AUTOSAR XML (schema 00046)
package /ComponentTypes
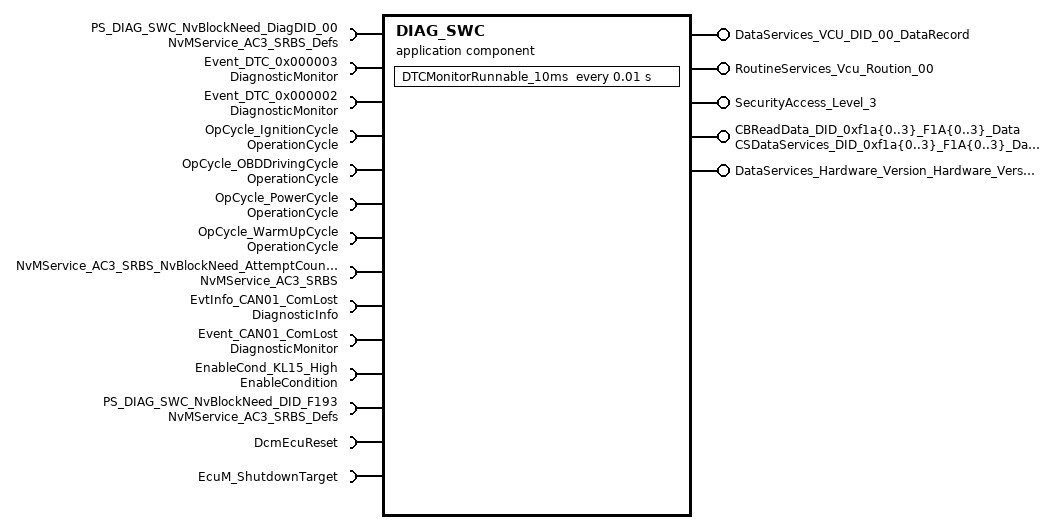
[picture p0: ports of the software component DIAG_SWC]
  application sw component type DIAG_SWC
    provide port DataServices_VCU_DID_00_DataRecord: provided-interface=DataServices_VCU_DID_00_DataRecord
      provided-com-specs:
        operation=ReadData, queue-length=1
        operation=ConditionCheckRead, queue-length=1
        operation=WriteData, queue-length=1
    require port PS_DIAG_SWC_NvBlockNeed_DiagDID_00: required-com-specs=[GetErrorStatus, SetRamBlockStatus, ReadBlock, WriteBlock, RestoreBlockDefaults, InvalidateNvBlock, EraseBlock], required-interface=NvMService_AC3_SRBS_Defs
    provide port RoutineServices_Vcu_Roution_00: provided-interface=RoutineServices_Vcu_Roution_00
      provided-com-specs:
        operation=Start, queue-length=1
        operation=Stop, queue-length=1
        operation=RequestResults, queue-length=1
    6 x require port:
      Event_DTC_0x000003: required-interface=DiagnosticMonitor
        required-com-specs:
          SetEventStatus
          ResetEventStatus
          ResetEventDebounceStatus
          GetEventUdsStatus
          GetEventStatus
          GetEventFailed
          GetEventTested
          GetDTCOfEvent
          GetFaultDetectionCounter
          GetEventFreezeFrameDataEx
          GetEventExtendedDataRecordEx
      Event_DTC_0x000002: required-interface=DiagnosticMonitor
        required-com-specs:
          SetEventStatus
          ResetEventStatus
          ResetEventDebounceStatus
          GetEventUdsStatus
          GetEventStatus
          GetEventFailed
          GetEventTested
          GetDTCOfEvent
          GetFaultDetectionCounter
          GetEventFreezeFrameDataEx
          GetEventExtendedDataRecordEx
      OpCycle_IgnitionCycle: required-com-specs=[GetOperationCycleState, SetOperationCycleState], required-interface=OperationCycle
      OpCycle_OBDDrivingCycle: required-com-specs=[GetOperationCycleState, SetOperationCycleState], required-interface=OperationCycle
      OpCycle_PowerCycle: required-com-specs=[GetOperationCycleState, SetOperationCycleState], required-interface=OperationCycle
      OpCycle_WarmUpCycle: required-com-specs=[GetOperationCycleState, SetOperationCycleState], required-interface=OperationCycle
    provide port SecurityAccess_Level_3: provided-interface=SecurityAccess_Level_3
      provided-com-specs:
        operation=GetSeed, queue-length=1
        operation=CompareKey, queue-length=1
        operation=GetSecurityAttemptCounter, queue-length=1
        operation=SetSecurityAttemptCounter, queue-length=1
    require port NvMService_AC3_SRBS_NvBlockNeed_AttemptCounter: required-com-specs=[WriteBlock, SetRamBlockStatus, ReadBlock, InvalidateNvBlock, GetErrorStatus, EraseBlock], required-interface=NvMService_AC3_SRBS
    4 x provide port, all with server-com-spec{operation=ReadData, queue-length=1}:
      CBReadData_DID_0xf1a{0..3}_F1A{0..3}_Data: provided-interface=CSDataServices_DID_0xf1a{0..3}_F1A{0..3}_Data
    4 x require port:
      EvtInfo_CAN01_ComLost: required-interface=DiagnosticInfo
        required-com-specs:
          GetEventUdsStatus
          GetEventStatus
          GetEventFailed
          GetEventTested
          GetDTCOfEvent
          GetFaultDetectionCounter
          GetEventFreezeFrameDataEx
          GetEventExtendedDataRecordEx
          GetEventEnableCondition
          GetDebouncingOfEvent
          GetMonitorStatus
      Event_CAN01_ComLost: required-interface=DiagnosticMonitor
        required-com-specs:
          SetEventStatus
          ResetEventStatus
          ResetEventDebounceStatus
          GetEventUdsStatus
          GetEventStatus
          GetEventFailed
          GetEventTested
          GetDTCOfEvent
          GetFaultDetectionCounter
          GetEventFreezeFrameDataEx
          GetEventExtendedDataRecordEx
      EnableCond_KL15_High: client-com-spec=SetEnableCondition, required-interface=EnableCondition
      PS_DIAG_SWC_NvBlockNeed_DID_F193: required-com-specs=[GetErrorStatus, SetRamBlockStatus, ReadBlock, WriteBlock, RestoreBlockDefaults, InvalidateNvBlock, EraseBlock], required-interface=NvMService_AC3_SRBS_Defs
    provide port DataServices_Hardware_Version_Hardware_Version_Number: provided-interface=DataServices_Hardware_Version_Hardware_Version_Number
      provided-com-specs:
        operation=ReadData, queue-length=1
        operation=ConditionCheckRead, queue-length=1
        operation=WriteData, queue-length=1
    require port DcmEcuReset: mode-switch-receiver-com-spec=DcmEcuReset, required-interface=DcmEcuReset
    require port EcuM_ShutdownTarget: required-com-specs=[SelectShutdownTarget, GetShutdownTarget, GetLastShutdownTarget, SelectShutdownCause, GetShutdownCause], required-interface=EcuM_ShutdownTarget
    behavior DIAG_SWC_InternalBehavior
      ar-typed-per-instance-memorys:
        data NvBlockNeed_DiagDID_00_MirrorBlock: sw-calibration-access=READ-WRITE, type=NvM_Arry4Bytes
        data NvBlockNeed_AttemptCounter_MirrorBlock: sw-calibration-access=READ-WRITE, type=uint8
        data NvBlockNeed_DID_F193_MirrorBlock: sw-calibration-access=READ-ONLY, type=NvM_Arry4Bytes
      6 x operation invoked event:
        OIT_DataServices_VCU_DID_00_DataRecord_WriteData_DataServices_VCU_DID_00_DataRecord_WriteData: start-on-event=DataServices_VCU_DID_00_DataRecord_WriteData, operation=DataServices_VCU_DID_00_DataRecord.WriteData
        OIT_DataServices_VCU_DID_00_DataRecord_ConditionCheckRead_DataServices_VCU_DID_00_DataRecord_ConditionCheckRead: start-on-event=DataServices_VCU_DID_00_DataRecord_ConditionCheckRead, operation=DataServices_VCU_DID_00_DataRecord.ConditionCheckRead
        OIT_DataServices_VCU_DID_00_DataRecord_ReadData_DataServices_VCU_DID_00_DataRecord_ReadData: start-on-event=DataServices_VCU_DID_00_DataRecord_ReadData, operation=DataServices_VCU_DID_00_DataRecord.ReadData
        OIT_RoutineServices_Vcu_Roution_00_RequestResults_RoutineServices_Vcu_Roution_00_RequestResults: start-on-event=RoutineServices_Vcu_Roution_00_RequestResults, operation=RoutineServices_Vcu_Roution_00.RequestResults
        OIT_RoutineServices_Vcu_Roution_00_Stop_RoutineServices_Vcu_Roution_00_Stop: start-on-event=RoutineServices_Vcu_Roution_00_Stop, operation=RoutineServices_Vcu_Roution_00.Stop
        OIT_RoutineServices_Vcu_Roution_00_Start_RoutineServices_Vcu_Roution_00_Start: start-on-event=RoutineServices_Vcu_Roution_00_Start, operation=RoutineServices_Vcu_Roution_00.Start
      init event DIAG_SWC_InitEvent: start-on-event=DIAG_SWC_Init
      timing event TMT_DTCMonitorRunnable_10ms: start-on-event=DTCMonitorRunnable_10ms, period=0.01
      11 x operation invoked event:
        OIT_SecurityAccess_Level_3_SetSecurityAttemptCounter_SecurityAccess_Level_3_SetSecurityAttemptCounter: start-on-event=SecurityAccess_Level_3_SetSecurityAttemptCounter, operation=SecurityAccess_Level_3.SetSecurityAttemptCounter
        OIT_SecurityAccess_Level_3_GetSecurityAttemptCounter_SecurityAccess_Level_3_GetSecurityAttemptCounter: start-on-event=SecurityAccess_Level_3_GetSecurityAttemptCounter, operation=SecurityAccess_Level_3.GetSecurityAttemptCounter
        OIT_SecurityAccess_Level_3_CompareKey_SecurityAccess_Level_3_CompareKey: start-on-event=SecurityAccess_Level_3_CompareKey, operation=SecurityAccess_Level_3.CompareKey
        OIT_SecurityAccess_Level_3_GetSeed_SecurityAccess_Level_3_GetSeed: start-on-event=SecurityAccess_Level_3_GetSeed, operation=SecurityAccess_Level_3.GetSeed
        OIT_CBReadData_DID_0xf1a{0..3}_F1A{0..3}_Data_ReadData_CBReadData_DID_0xf1a{0..3}_F1A{0..3}_Data_ReadData: start-on-event=CBReadData_DID_0xf1a{0..3}_F1A{0..3}_Data_ReadData, operation=CBReadData_DID_0xf1a{0..3}_F1A{0..3}_Data.ReadData
        OIT_DataServices_Hardware_Version_Hardware_Version_Number_WriteData_DataServices_Hardware_Version_Hardware_Version_Numbe125FF288: start-on-event=DataServices_Hardware_Version_Hardware_Version_Number_WriteData, operation=DataServices_Hardware_Version_Hardware_Version_Number.WriteData
        OIT_DataServices_Hardware_Version_Hardware_Version_Number_ConditionCheckRead_DataServices_Hardware_Version_Hardware_Vers10245F7A: start-on-event=DataServices_Hardware_Version_Hardware_Version_Number_ConditionCheckRead, operation=DataServices_Hardware_Version_Hardware_Version_Number.ConditionCheckRead
        OIT_DataServices_Hardware_Version_Hardware_Version_Number_ReadData_DataServices_Hardware_Version_Hardware_Version_Number62630144: start-on-event=DataServices_Hardware_Version_Hardware_Version_Number_ReadData, operation=DataServices_Hardware_Version_Hardware_Version_Number.ReadData
      swc mode switch event MST_EcuReset_JumpFBL_0: start-on-event=EcuReset_JumpFBL, activation=ON-ENTRY, mode=DcmEcuReset.DcmEcuReset.JUMPTOBOOTLOADER
      swc mode switch event MST_EcuReset_JumpFBL_1: start-on-event=EcuReset_JumpFBL, activation=ON-ENTRY, mode=DcmEcuReset.DcmEcuReset.EXECUTE
      20 x runnable:
        DataServices_VCU_DID_00_DataRecord_WriteData
          sync call SC_PS_DIAG_SWC_NvBlockNeed_DiagDID_00_GetErrorStatus: operation=PS_DIAG_SWC_NvBlockNeed_DiagDID_00.GetErrorStatus
          sync call SC_PS_DIAG_SWC_NvBlockNeed_DiagDID_00_SetRamBlockStatus: operation=PS_DIAG_SWC_NvBlockNeed_DiagDID_00.SetRamBlockStatus
          sync call SC_PS_DIAG_SWC_NvBlockNeed_DiagDID_00_WriteBlock: operation=PS_DIAG_SWC_NvBlockNeed_DiagDID_00.WriteBlock
        DataServices_VCU_DID_00_DataRecord_ConditionCheckRead
          sync call SC_PS_DIAG_SWC_NvBlockNeed_DiagDID_00_GetErrorStatus: operation=PS_DIAG_SWC_NvBlockNeed_DiagDID_00.GetErrorStatus
        DataServices_VCU_DID_00_DataRecord_ReadData
          sync call SC_PS_DIAG_SWC_NvBlockNeed_DiagDID_00_ReadBlock: operation=PS_DIAG_SWC_NvBlockNeed_DiagDID_00.ReadBlock
        RoutineServices_Vcu_Roution_00_RequestResults
        RoutineServices_Vcu_Roution_00_Stop
        RoutineServices_Vcu_Roution_00_Start
        DIAG_SWC_Init
          8 x sync call:
            SC_OpCycle_IgnitionCycle_GetOperationCycleState: operation=OpCycle_IgnitionCycle.GetOperationCycleState
            SC_OpCycle_IgnitionCycle_SetOperationCycleState: operation=OpCycle_IgnitionCycle.SetOperationCycleState
            SC_OpCycle_OBDDrivingCycle_GetOperationCycleState: operation=OpCycle_OBDDrivingCycle.GetOperationCycleState
            SC_OpCycle_OBDDrivingCycle_SetOperationCycleState: operation=OpCycle_OBDDrivingCycle.SetOperationCycleState
            SC_OpCycle_PowerCycle_GetOperationCycleState: operation=OpCycle_PowerCycle.GetOperationCycleState
            SC_OpCycle_PowerCycle_SetOperationCycleState: operation=OpCycle_PowerCycle.SetOperationCycleState
            SC_OpCycle_WarmUpCycle_GetOperationCycleState: operation=OpCycle_WarmUpCycle.GetOperationCycleState
            SC_OpCycle_WarmUpCycle_SetOperationCycleState: operation=OpCycle_WarmUpCycle.SetOperationCycleState
        DTCMonitorRunnable_10ms
          9 x sync call:
            SC_Event_DTC_0x000002_GetEventStatus: operation=Event_DTC_0x000002.GetEventStatus
            SC_Event_DTC_0x000002_SetEventStatus: operation=Event_DTC_0x000002.SetEventStatus
            SC_Event_DTC_0x000003_GetEventStatus: operation=Event_DTC_0x000003.GetEventStatus
            SC_Event_DTC_0x000003_SetEventStatus: operation=Event_DTC_0x000003.SetEventStatus
            SC_Event_CAN01_ComLost_GetEventStatus: operation=Event_CAN01_ComLost.GetEventStatus
            SC_Event_CAN01_ComLost_SetEventStatus: operation=Event_CAN01_ComLost.SetEventStatus
            SC_EnableCond_KL15_High_SetEnableCondition: operation=EnableCond_KL15_High.SetEnableCondition
            SC_OpCycle_IgnitionCycle_GetOperationCycleState: operation=OpCycle_IgnitionCycle.GetOperationCycleState
            SC_OpCycle_IgnitionCycle_SetOperationCycleState: operation=OpCycle_IgnitionCycle.SetOperationCycleState
        SecurityAccess_Level_3_SetSecurityAttemptCounter
          sync call SC_NvMService_AC3_SRBS_NvBlockNeed_AttemptCounter_ReadBlock: operation=NvMService_AC3_SRBS_NvBlockNeed_AttemptCounter.ReadBlock
          sync call SC_NvMService_AC3_SRBS_NvBlockNeed_AttemptCounter_SetRamBlockStatus: operation=NvMService_AC3_SRBS_NvBlockNeed_AttemptCounter.SetRamBlockStatus
          sync call SC_NvMService_AC3_SRBS_NvBlockNeed_AttemptCounter_WriteBlock: operation=NvMService_AC3_SRBS_NvBlockNeed_AttemptCounter.WriteBlock
        SecurityAccess_Level_3_GetSecurityAttemptCounter
          sync call SC_NvMService_AC3_SRBS_NvBlockNeed_AttemptCounter_ReadBlock: operation=NvMService_AC3_SRBS_NvBlockNeed_AttemptCounter.ReadBlock
          sync call SC_NvMService_AC3_SRBS_NvBlockNeed_AttemptCounter_SetRamBlockStatus: operation=NvMService_AC3_SRBS_NvBlockNeed_AttemptCounter.SetRamBlockStatus
          sync call SC_NvMService_AC3_SRBS_NvBlockNeed_AttemptCounter_WriteBlock: operation=NvMService_AC3_SRBS_NvBlockNeed_AttemptCounter.WriteBlock
        SecurityAccess_Level_3_CompareKey
        SecurityAccess_Level_3_GetSeed
        CBReadData_DID_0xf1a{0..3}_F1A{0..3}_Data_ReadData
        DataServices_Hardware_Version_Hardware_Version_Number_WriteData
          sync call SC_PS_DIAG_SWC_NvBlockNeed_DID_F193_WriteBlock: operation=PS_DIAG_SWC_NvBlockNeed_DID_F193.WriteBlock
          sync call SC_PS_DIAG_SWC_NvBlockNeed_DID_F193_SetRamBlockStatus: operation=PS_DIAG_SWC_NvBlockNeed_DID_F193.SetRamBlockStatus
        DataServices_Hardware_Version_Hardware_Version_Number_ConditionCheckRead
        DataServices_Hardware_Version_Hardware_Version_Number_ReadData
          sync call SC_PS_DIAG_SWC_NvBlockNeed_DID_F193_ReadBlock: operation=PS_DIAG_SWC_NvBlockNeed_DID_F193.ReadBlock
        EcuReset_JumpFBL: mode-access-point=DcmEcuReset.DcmEcuReset
          sync call SC_EcuM_ShutdownTarget_SelectShutdownTarget: operation=EcuM_ShutdownTarget.SelectShutdownTarget
      swc service dependency NvBlockNeed_DiagDID_00
        assigned-datas:
          role=ramBlock, used-data-element=NvBlockNeed_DiagDID_00_MirrorBlock
          role=defaultValue, used-parameter-element=NvBlockNeed_DiagDID_00_DefaultValue
        service-needs:
          nv block needs NvBlockNeed_DiagDID_00: calc-ram-block-crc=false, check-static-block-id=false, n-data-sets=0, ram-block-status-control=API, readonly=false, reliability=ERROR-DETECTION, resistant-to-changed-sw=true, restore-at-start=true, store-at-shutdown=true, store-cyclic=false, store-emergency=false, store-immediate=false, use-auto-validation-at-shut-down=false, use-crc-comp-mechanism=false, write-only-once=false, write-verification=false
      swc service dependency NvBlockNeed_AttemptCounter: assigned-ports=role-based-port-assignment={port-prototype=NvMService_AC3_SRBS_NvBlockNeed_AttemptCounter, role=NvMService_AC3_SRBS}
        assigned-datas:
          role=ramBlock, used-data-element=NvBlockNeed_AttemptCounter_MirrorBlock
          role=defaultValue, used-parameter-element=NvBlockNeed_AttemptCounter_DefaultValue
        service-needs:
          nv block needs NvBlockNeed_AttemptCounter: calc-ram-block-crc=false, check-static-block-id=false, n-data-sets=0, n-rom-blocks=1, ram-block-status-control=API, readonly=false, reliability=ERROR-DETECTION, resistant-to-changed-sw=true, restore-at-start=true, store-at-shutdown=true, store-cyclic=false, store-emergency=false, store-immediate=false, use-auto-validation-at-shut-down=false, use-crc-comp-mechanism=false, write-only-once=false, write-verification=false
      swc service dependency NvBlockNeed_DID_F193
        assigned-datas:
          role=ramBlock, used-data-element=NvBlockNeed_DID_F193_MirrorBlock
          role=defaultValue, used-parameter-element=NvBlockNeed_DID_F193_DefaultValue
        service-needs:
          nv block needs NvBlockNeed: calc-ram-block-crc=false, check-static-block-id=false, n-data-sets=0, ram-block-status-control=API, readonly=false, reliability=NO-PROTECTION, resistant-to-changed-sw=true, restore-at-start=true, store-at-shutdown=true, store-cyclic=false, store-emergency=false, store-immediate=false, use-auto-validation-at-shut-down=false, use-crc-comp-mechanism=false, write-only-once=false, write-verification=false
      shared-parameters:
        parameter data prototype NvBlockNeed_DiagDID_00_DefaultValue: sw-calibration-access=READ-WRITE, type=NvM_Arry4Bytes, init-value=[0, 0, 0, 0]
        parameter data prototype NvBlockNeed_AttemptCounter_DefaultValue: sw-calibration-access=READ-WRITE, type=uint8, init-value=0
        parameter data prototype NvBlockNeed_DID_F193_DefaultValue: sw-calibration-access=READ-WRITE, type=NvM_Arry4Bytes, init-value=[0, 0, 0, 0]
  swc implementation DIAG_SWC_Implementation: behavior=DIAG_SWC_InternalBehavior
